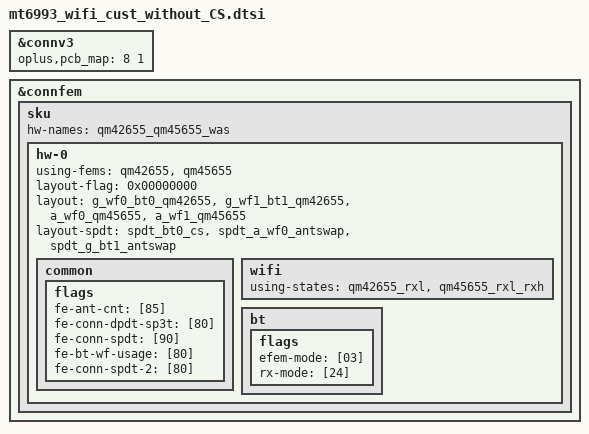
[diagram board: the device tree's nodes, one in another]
// SPDX-License-Identifier: (GPL-2.0 OR MIT)
/*
 * Copyright (C) 2020 MediaTek Inc.
 */

&connv3 {
	oplus,pcb_map = <8 1>;
};

&connfem {
	sku {
		hw-names =
			"qm42655_qm45655_was";	/* [0] QM42655/QM45655, 2G+2A, BT/Wi-Fi AntSwap */

		/***************************************************************
		 * [HW][0] QM42655/QM45655, 2G+2A, BT/Wi-Fi AntSwap
		 **************************************************************/
		hw-0 {
			using-fems =
				<&qm42655>,
				<&qm45655>;

			layout-flag = <0x00000000>;
			layout =
				<&g_wf0_bt0_qm42655>,
				<&g_wf1_bt1_qm42655>,
				<&a_wf0_qm45655>,
				<&a_wf1_qm45655>;

			layout-spdt =
				<&spdt_bt0_cs>,
				<&spdt_a_wf0_antswap>,
				<&spdt_g_bt1_antswap>;

			common {
				flags {
					fe-ant-cnt = [85];
					fe-conn-dpdt-sp3t = [80];
					fe-conn-spdt = [90];
					fe-bt-wf-usage = [80];
					fe-conn-spdt-2 = [80]; //Bit [0] = 0, dual antenna CS is not supported
				};
			};

			wifi {
				using-states =
					<&qm42655_rxl>,
					<&qm45655_rxl_rxh>;
			};

			bt {
				flags {
					efem-mode = [03]; /* 3:epa_elna, 2:epa, 1:elna, 0:bypass */
					rx-mode = [24]; /* 0x24: G-band RxL */
				};
			};
		};
	};
};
